VERSION ""

NS_ :

BS_:

BU_: Arduino

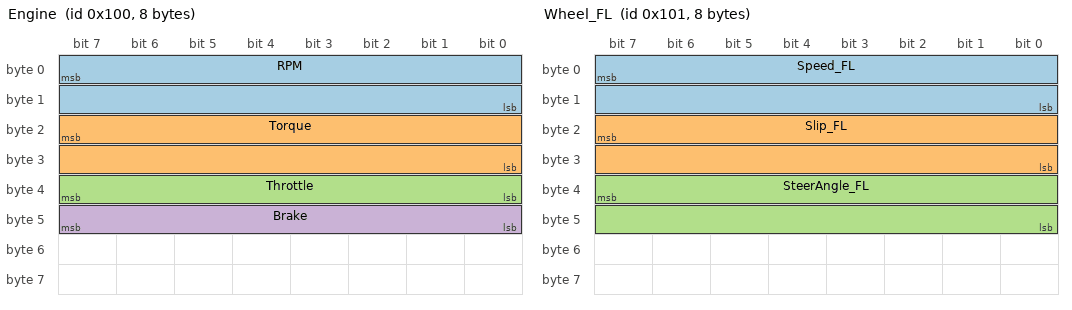
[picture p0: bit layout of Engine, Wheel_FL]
BO_ 256 Engine: 8 Arduino
 SG_ RPM : 7|16@0+ (1,0) [0|65535] "rpm" Vector__XXX
 SG_ Torque : 23|16@0- (0.1,0) [-3276.8|3276.7] "Nm" Vector__XXX
 SG_ Throttle : 39|8@0+ (0.003922,0) [0|1] "" Vector__XXX
 SG_ Brake : 47|8@0+ (0.003922,0) [0|1] "" Vector__XXX

BO_ 257 Wheel_FL: 8 Arduino
 SG_ Speed_FL : 7|16@0- (0.01,0) [-327.68|327.67] "km/h" Vector__XXX
 SG_ Slip_FL : 23|16@0- (0.001,0) [-32.768|32.767] "" Vector__XXX
 SG_ SteerAngle_FL : 39|16@0- (0.1,0) [-3276.8|3276.7] "deg" Vector__XXX

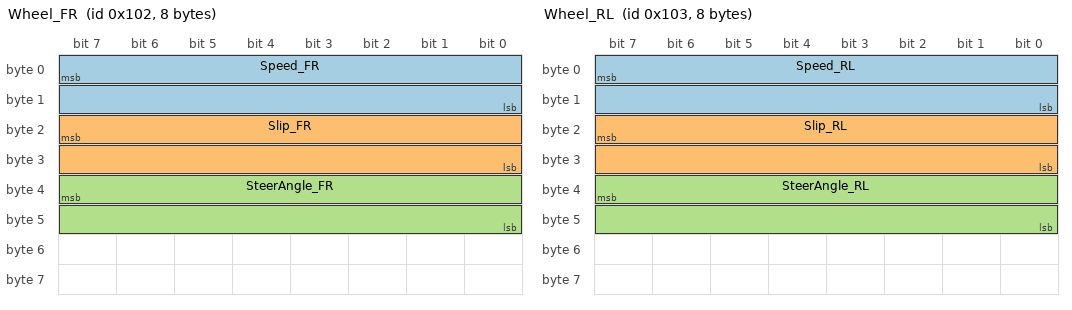
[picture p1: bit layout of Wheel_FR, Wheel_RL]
BO_ 258 Wheel_FR: 8 Arduino
 SG_ Speed_FR : 7|16@0- (0.01,0) [-327.68|327.67] "km/h" Vector__XXX
 SG_ Slip_FR : 23|16@0- (0.001,0) [-32.768|32.767] "" Vector__XXX
 SG_ SteerAngle_FR : 39|16@0- (0.1,0) [-3276.8|3276.7] "deg" Vector__XXX

BO_ 259 Wheel_RL: 8 Arduino
 SG_ Speed_RL : 7|16@0- (0.01,0) [-327.68|327.67] "km/h" Vector__XXX
 SG_ Slip_RL : 23|16@0- (0.001,0) [-32.768|32.767] "" Vector__XXX
 SG_ SteerAngle_RL : 39|16@0- (0.1,0) [-3276.8|3276.7] "deg" Vector__XXX

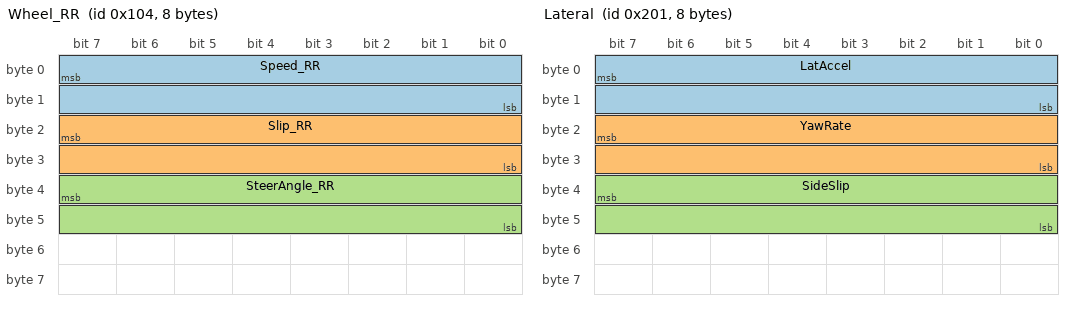
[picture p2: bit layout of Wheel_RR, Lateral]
BO_ 260 Wheel_RR: 8 Arduino
 SG_ Speed_RR : 7|16@0- (0.01,0) [-327.68|327.67] "km/h" Vector__XXX
 SG_ Slip_RR : 23|16@0- (0.001,0) [-32.768|32.767] "" Vector__XXX
 SG_ SteerAngle_RR : 39|16@0- (0.1,0) [-3276.8|3276.7] "deg" Vector__XXX

BO_ 512 Steering: 8 Arduino
 SG_ SteerSW_Angle : 7|16@0- (0.1,0) [-3276.8|3276.7] "deg" Vector__XXX
 SG_ SteerRW_Angle : 23|16@0- (0.01,0) [-327.68|327.67] "deg" Vector__XXX

BO_ 513 Lateral: 8 Arduino
 SG_ LatAccel : 7|16@0- (0.01,0) [-327.68|327.67] "m/s^2" Vector__XXX
 SG_ YawRate : 23|16@0- (0.001,0) [-32.768|32.767] "rad/s" Vector__XXX
 SG_ SideSlip : 39|16@0- (0.01,0) [-327.68|327.67] "deg" Vector__XXX

BO_ 768 Vehicle: 8 Arduino
 SG_ VehicleSpeed : 7|16@0- (0.01,0) [-327.68|327.67] "km/h" Vector__XXX
 SG_ LongAccel : 23|16@0- (0.01,0) [-327.68|327.67] "m/s^2" Vector__XXX

CM_ BU_ Arduino "SimpleVehicle Arduino CAN node (MCP2515, 500 kbps)";

CM_ BO_ 256 "Engine state (100 Hz, 10 ms cycle)";
CM_ BO_ 257 "Front-left wheel dynamics (100 Hz, 10 ms cycle)";
CM_ BO_ 258 "Front-right wheel dynamics (100 Hz, 10 ms cycle)";
CM_ BO_ 259 "Rear-left wheel dynamics (100 Hz, 10 ms cycle)";
CM_ BO_ 260 "Rear-right wheel dynamics (100 Hz, 10 ms cycle)";
CM_ BO_ 512 "Steering angles (100 Hz, 10 ms cycle)";
CM_ BO_ 513 "Lateral dynamics (100 Hz, 10 ms cycle)";
CM_ BO_ 768 "Vehicle longitudinal state (100 Hz, 10 ms cycle)";

CM_ SG_ 256 RPM "Engine speed [rpm], raw uint16, 1 rpm/bit";
CM_ SG_ 256 Torque "Engine output torque, signed int16, 0.1 Nm/bit";
CM_ SG_ 256 Throttle "Throttle pedal position, uint8, 0=released / 1=full (factor 1/255)";
CM_ SG_ 256 Brake "Brake pedal position, uint8, 0=released / 1=full (factor 1/255)";
CM_ SG_ 257 Speed_FL "Front-left wheel speed, signed int16, 0.01 km/h/bit";
CM_ SG_ 257 Slip_FL "Front-left wheel slip ratio, signed int16, 0.001/bit (0=free-rolling)";
CM_ SG_ 257 SteerAngle_FL "Front-left wheel steer angle, signed int16, 0.1 deg/bit";
CM_ SG_ 258 Speed_FR "Front-right wheel speed, signed int16, 0.01 km/h/bit";
CM_ SG_ 258 Slip_FR "Front-right wheel slip ratio, signed int16, 0.001/bit";
CM_ SG_ 258 SteerAngle_FR "Front-right wheel steer angle, signed int16, 0.1 deg/bit";
CM_ SG_ 259 Speed_RL "Rear-left wheel speed, signed int16, 0.01 km/h/bit";
CM_ SG_ 259 Slip_RL "Rear-left wheel slip ratio, signed int16, 0.001/bit";
CM_ SG_ 259 SteerAngle_RL "Rear-left wheel steer angle, signed int16, 0.1 deg/bit";
CM_ SG_ 260 Speed_RR "Rear-right wheel speed, signed int16, 0.01 km/h/bit";
CM_ SG_ 260 Slip_RR "Rear-right wheel slip ratio, signed int16, 0.001/bit";
CM_ SG_ 260 SteerAngle_RR "Rear-right wheel steer angle, signed int16, 0.1 deg/bit";
CM_ SG_ 512 SteerSW_Angle "Steering wheel angle, signed int16, 0.1 deg/bit (+CW)";
CM_ SG_ 512 SteerRW_Angle "Road wheel angle, signed int16, 0.01 deg/bit (+CW)";
CM_ SG_ 513 LatAccel "Lateral acceleration, signed int16, 0.01 m/s^2/bit (+left)";
CM_ SG_ 513 YawRate "Yaw rate, signed int16, 0.001 rad/s/bit (+CCW)";
CM_ SG_ 513 SideSlip "Vehicle side-slip angle (beta), signed int16, 0.01 deg/bit";
CM_ SG_ 768 VehicleSpeed "Vehicle speed derived from wheel speeds, signed int16, 0.01 km/h/bit";
CM_ SG_ 768 LongAccel "Longitudinal acceleration, signed int16, 0.01 m/s^2/bit (+forward)";

BA_DEF_ BO_ "GenMsgCycleTime" INT 0 10000;
BA_DEF_DEF_ "GenMsgCycleTime" 0;

BA_ "GenMsgCycleTime" BO_ 256 10;
BA_ "GenMsgCycleTime" BO_ 257 10;
BA_ "GenMsgCycleTime" BO_ 258 10;
BA_ "GenMsgCycleTime" BO_ 259 10;
BA_ "GenMsgCycleTime" BO_ 260 10;
BA_ "GenMsgCycleTime" BO_ 512 10;
BA_ "GenMsgCycleTime" BO_ 513 10;
BA_ "GenMsgCycleTime" BO_ 768 10;
